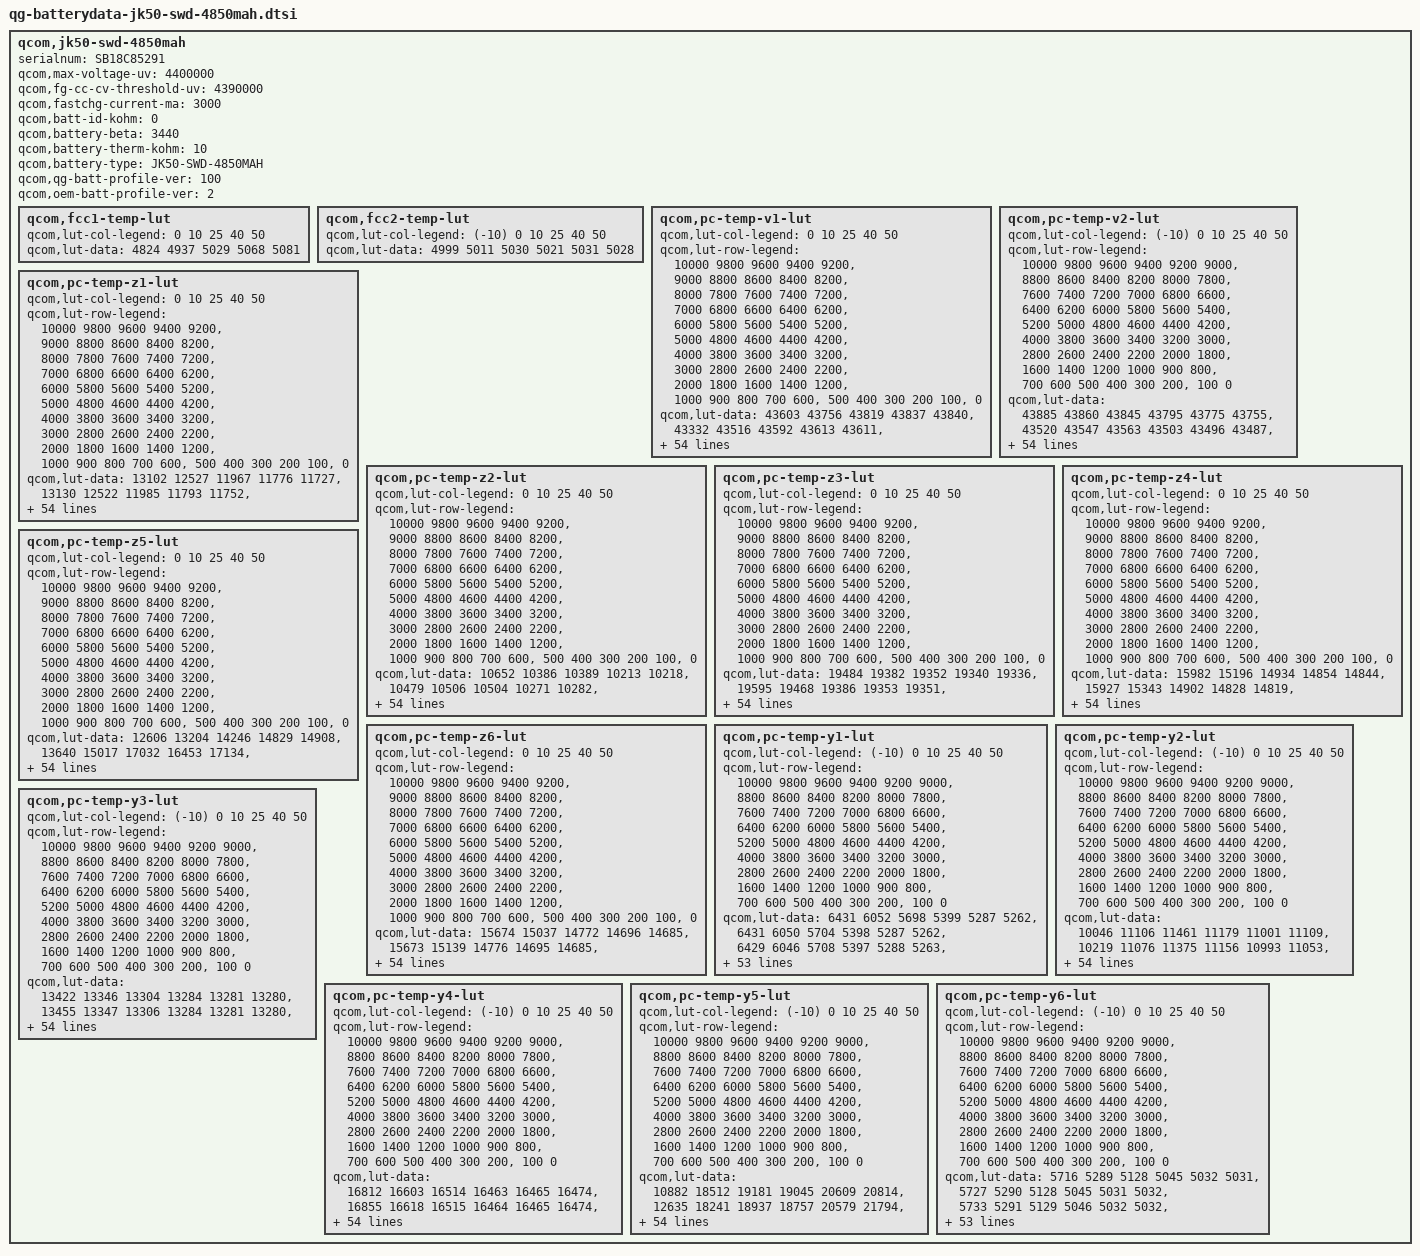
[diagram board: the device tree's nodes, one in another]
qcom,jk50-swd-4850mah {
    /* 4625982_SunWoda_P270AE_4850mAH_PMI632_averaged_MasterSlave_Jun9th2020 */
    serialnum = "SB18C85291";
    qcom,max-voltage-uv = <4400000>;
    qcom,fg-cc-cv-threshold-uv = <4390000>;
    qcom,fastchg-current-ma = <3000>;
    qcom,batt-id-kohm = <0>;
    qcom,battery-beta = <3440>;
    qcom,battery-therm-kohm = <10>;
    qcom,battery-type = "JK50-SWD-4850MAH";
    qcom,qg-batt-profile-ver = <100>;
    qcom,oem-batt-profile-ver = <2>;

	qcom,fcc1-temp-lut {
		qcom,lut-col-legend = <0 10 25 40 50>;
		qcom,lut-data = <4824 4937 5029 5068 5081>;
	};

	qcom,fcc2-temp-lut {
		qcom,lut-col-legend = <(-10) 0 10 25 40 50>;
		qcom,lut-data = <4999 5011 5030 5021 5031 5028>;
	};

	qcom,pc-temp-v1-lut {
		qcom,lut-col-legend = <0 10 25 40 50>;
		qcom,lut-row-legend = <10000 9800 9600 9400 9200>,
			<9000 8800 8600 8400 8200>,
			<8000 7800 7600 7400 7200>,
			<7000 6800 6600 6400 6200>,
			<6000 5800 5600 5400 5200>,
			<5000 4800 4600 4400 4200>,
			<4000 3800 3600 3400 3200>,
			<3000 2800 2600 2400 2200>,
			<2000 1800 1600 1400 1200>,
			<1000 900 800 700 600>,
			<500 400 300 200 100>,
			<0>;
		qcom,lut-data = <43603 43756 43819 43837 43840>,
			<43332 43516 43592 43613 43611>,
			<43073 43260 43358 43387 43393>,
			<42828 43019 43116 43153 43160>,
			<42594 42777 42871 42916 42925>,
			<42367 42538 42631 42678 42691>,
			<42146 42306 42393 42441 42457>,
			<41930 42082 42158 42205 42223>,
			<41716 41863 41927 41973 41990>,
			<41505 41643 41700 41743 41756>,
			<41311 41424 41474 41515 41527>,
			<41149 41227 41256 41291 41303>,
			<40979 41066 41060 41075 41084>,
			<40729 40893 40888 40872 40871>,
			<40397 40628 40693 40672 40663>,
			<40135 40304 40424 40464 40465>,
			<39962 40082 40161 40257 40275>,
			<39822 39942 39999 40076 40094>,
			<39697 39818 39879 39916 39921>,
			<39591 39690 39745 39757 39752>,
			<39477 39561 39596 39600 39593>,
			<39345 39383 39421 39433 39430>,
			<39205 39122 39160 39212 39222>,
			<39063 38889 38868 38944 38967>,
			<38915 38726 38717 38767 38775>,
			<38770 38596 38637 38668 38651>,
			<38620 38512 38564 38583 38550>,
			<38487 38453 38484 38483 38451>,
			<38406 38399 38407 38386 38362>,
			<38348 38345 38336 38301 38283>,
			<38304 38294 38270 38229 38213>,
			<38268 38247 38207 38163 38148>,
			<38238 38204 38150 38108 38090>,
			<38212 38165 38096 38055 38034>,
			<38190 38129 38050 38001 37975>,
			<38166 38094 38007 37947 37913>,
			<38141 38060 37964 37893 37852>,
			<38111 38026 37924 37844 37797>,
			<38064 37979 37872 37785 37732>,
			<37986 37899 37790 37697 37638>,
			<37889 37797 37684 37586 37522>,
			<37766 37682 37572 37471 37403>,
			<37624 37548 37446 37344 37275>,
			<37465 37392 37295 37197 37121>,
			<37327 37246 37151 37058 36981>,
			<37224 37153 37061 36974 36913>,
			<37195 37123 37032 36944 36888>,
			<37176 37099 37014 36924 36864>,
			<37149 37086 36996 36903 36842>,
			<37107 37049 36953 36852 36782>,
			<36918 36843 36738 36608 36514>,
			<36488 36418 36313 36171 36071>,
			<35914 35849 35743 35598 35495>,
			<35136 35066 34962 34814 34707>,
			<33915 33848 33751 33593 33479>,
			<30000 30000 30000 30000 30000>;
	};

	qcom,pc-temp-v2-lut {
		qcom,lut-col-legend = <(-10) 0 10 25 40 50>;
		qcom,lut-row-legend = <10000 9800 9600 9400 9200 9000>,
			<8800 8600 8400 8200 8000 7800>,
			<7600 7400 7200 7000 6800 6600>,
			<6400 6200 6000 5800 5600 5400>,
			<5200 5000 4800 4600 4400 4200>,
			<4000 3800 3600 3400 3200 3000>,
			<2800 2600 2400 2200 2000 1800>,
			<1600 1400 1200 1000 900 800>,
			<700 600 500 400 300 200>,
			<100 0>;
		qcom,lut-data = <43885 43860 43845 43795 43775 43755>,
			<43520 43547 43563 43503 43496 43487>,
			<43189 43251 43292 43227 43229 43228>,
			<42899 42976 43032 42968 42976 42980>,
			<42644 42719 42782 42724 42735 42742>,
			<42394 42470 42536 42485 42497 42505>,
			<42136 42224 42293 42246 42260 42267>,
			<41883 41985 42055 42011 42024 42029>,
			<41637 41754 41826 41780 41792 41796>,
			<41398 41529 41602 41552 41563 41564>,
			<41197 41318 41382 41329 41337 41337>,
			<41046 41125 41162 41110 41114 41114>,
			<40877 40930 40951 40898 40898 40897>,
			<40596 40724 40768 40707 40693 40690>,
			<40235 40503 40589 40523 40494 40488>,
			<39925 40226 40359 40313 40297 40293>,
			<39645 39863 40065 40075 40100 40102>,
			<39421 39579 39807 39868 39916 39920>,
			<39268 39425 39620 39725 39754 39754>,
			<39137 39299 39449 39589 39592 39588>,
			<38989 39141 39256 39393 39402 39404>,
			<38830 38965 39055 39147 39191 39205>,
			<38668 38803 38880 38932 38987 39005>,
			<38488 38658 38730 38749 38781 38791>,
			<38325 38524 38595 38592 38602 38603>,
			<38216 38403 38475 38468 38471 38470>,
			<38132 38292 38367 38363 38363 38361>,
			<38066 38186 38269 38268 38265 38260>,
			<38015 38079 38178 38181 38174 38167>,
			<37969 37991 38095 38102 38093 38083>,
			<37924 37931 38017 38027 38021 38011>,
			<37881 37882 37946 37958 37955 37943>,
			<37837 37842 37883 37897 37891 37880>,
			<37791 37808 37826 37843 37830 37821>,
			<37744 37778 37778 37788 37765 37754>,
			<37696 37751 37739 37733 37694 37671>,
			<37644 37722 37700 37675 37620 37581>,
			<37585 37683 37656 37612 37538 37487>,
			<37517 37634 37608 37545 37452 37390>,
			<37443 37573 37548 37470 37369 37302>,
			<37363 37495 37468 37387 37290 37225>,
			<37279 37383 37370 37292 37201 37137>,
			<37190 37219 37248 37179 37092 37029>,
			<37105 37092 37106 37042 36939 36873>,
			<37018 36986 36982 36921 36835 36774>,
			<36923 36895 36916 36874 36799 36740>,
			<36875 36849 36896 36862 36788 36730>,
			<36828 36804 36874 36847 36773 36713>,
			<36776 36742 36838 36820 36745 36684>,
			<36694 36648 36766 36747 36654 36578>,
			<36515 36470 36552 36504 36357 36256>,
			<36143 36096 36094 36014 35858 35745>,
			<35559 35497 35451 35380 35206 35084>,
			<34714 34662 34571 34523 34306 34164>,
			<33378 33410 33306 33242 32978 32845>,
			<29173 28085 28060 28142 28137 28100>;
	};

	qcom,pc-temp-z1-lut {
		qcom,lut-col-legend = <0 10 25 40 50>;
		qcom,lut-row-legend = <10000 9800 9600 9400 9200>,
			<9000 8800 8600 8400 8200>,
			<8000 7800 7600 7400 7200>,
			<7000 6800 6600 6400 6200>,
			<6000 5800 5600 5400 5200>,
			<5000 4800 4600 4400 4200>,
			<4000 3800 3600 3400 3200>,
			<3000 2800 2600 2400 2200>,
			<2000 1800 1600 1400 1200>,
			<1000 900 800 700 600>,
			<500 400 300 200 100>,
			<0>;
		qcom,lut-data = <13102 12527 11967 11776 11727>,
			<13130 12522 11985 11793 11752>,
			<13140 12523 11983 11793 11754>,
			<13130 12522 11980 11793 11756>,
			<13096 12514 11977 11794 11758>,
			<13076 12492 11974 11795 11759>,
			<13070 12479 11971 11795 11761>,
			<13066 12476 11969 11796 11763>,
			<13061 12474 11967 11798 11767>,
			<13056 12472 11966 11802 11771>,
			<13049 12467 11971 11805 11775>,
			<13036 12462 11980 11810 11779>,
			<13018 12457 11981 11811 11782>,
			<12991 12450 11977 11811 11784>,
			<12954 12438 11974 11811 11785>,
			<12937 12421 11968 11812 11787>,
			<12936 12417 11964 11814 11789>,
			<12937 12424 11966 11816 11791>,
			<12940 12433 11972 11818 11793>,
			<12950 12446 11978 11821 11795>,
			<12963 12461 11984 11823 11797>,
			<12984 12465 11988 11825 11799>,
			<13004 12463 11990 11827 11802>,
			<13008 12463 11992 11828 11804>,
			<13002 12467 11995 11831 11807>,
			<12999 12473 11999 11834 11810>,
			<13002 12476 12004 11838 11813>,
			<13006 12479 12008 11842 11816>,
			<13014 12482 12014 11845 11819>,
			<13030 12492 12019 11848 11822>,
			<13040 12504 12024 11852 11825>,
			<13041 12511 12029 11856 11828>,
			<13042 12515 12035 11859 11832>,
			<13043 12521 12040 11863 11836>,
			<13048 12529 12046 11867 11840>,
			<13053 12537 12053 11872 11843>,
			<13064 12542 12059 11876 11846>,
			<13079 12547 12063 11879 11849>,
			<13091 12554 12068 11883 11852>,
			<13103 12567 12074 11887 11855>,
			<13113 12579 12080 11891 11858>,
			<13124 12585 12087 11895 11861>,
			<13138 12590 12095 11899 11864>,
			<13158 12600 12100 11903 11867>,
			<13166 12619 12107 11906 11870>,
			<13177 12617 12116 11909 11871>,
			<13163 12614 12113 11908 11871>,
			<13142 12623 12113 11909 11871>,
			<13142 12616 12117 11911 11874>,
			<13147 12631 12125 11915 11878>,
			<13173 12634 12129 11920 11883>,
			<13170 12653 12138 11929 11889>,
			<13213 12677 12156 11940 11899>,
			<13255 12701 12183 11957 11913>,
			<13255 12701 12183 11957 11913>,
			<13255 12701 12183 11957 11913>;
	};

	qcom,pc-temp-z2-lut {
		qcom,lut-col-legend = <0 10 25 40 50>;
		qcom,lut-row-legend = <10000 9800 9600 9400 9200>,
			<9000 8800 8600 8400 8200>,
			<8000 7800 7600 7400 7200>,
			<7000 6800 6600 6400 6200>,
			<6000 5800 5600 5400 5200>,
			<5000 4800 4600 4400 4200>,
			<4000 3800 3600 3400 3200>,
			<3000 2800 2600 2400 2200>,
			<2000 1800 1600 1400 1200>,
			<1000 900 800 700 600>,
			<500 400 300 200 100>,
			<0>;
		qcom,lut-data = <10652 10386 10389 10213 10218>,
			<10479 10506 10504 10271 10282>,
			<10383 10499 10530 10291 10237>,
			<10382 10496 10521 10353 10297>,
			<10384 10481 10511 10392 10365>,
			<10388 10443 10493 10399 10383>,
			<10398 10420 10469 10389 10344>,
			<10406 10526 10446 10376 10310>,
			<10401 10658 10422 10359 10314>,
			<10379 10606 10408 10341 10323>,
			<10359 10419 10415 10339 10320>,
			<10344 10361 10425 10349 10306>,
			<10328 10612 10419 10346 10294>,
			<10305 10848 10388 10297 10284>,
			<10277 10748 10373 10256 10277>,
			<10262 10500 10430 10296 10263>,
			<10261 10426 10494 10376 10228>,
			<10264 10427 10477 10381 10225>,
			<10272 10431 10417 10310 10246>,
			<10287 10453 10403 10268 10272>,
			<10305 10503 10463 10291 10296>,
			<10325 10562 10531 10323 10318>,
			<10349 10644 10570 10333 10334>,
			<10376 10690 10600 10338 10349>,
			<10409 10667 10584 10345 10409>,
			<10437 10630 10479 10357 11039>,
			<10464 10616 10419 10378 11620>,
			<10484 10608 10457 10543 11401>,
			<10486 10604 10512 10807 10861>,
			<10484 10598 10537 10826 10571>,
			<10482 10591 10555 10662 10418>,
			<10481 10592 10566 10498 10312>,
			<10479 10598 10576 10361 10226>,
			<10480 10606 10583 10263 10172>,
			<10483 10619 10579 10249 10175>,
			<10488 10633 10570 10257 10206>,
			<10494 10644 10570 10278 10248>,
			<10503 10652 10587 10340 10322>,
			<10515 10664 10612 10406 10400>,
			<10533 10687 10662 10458 10468>,
			<10549 10704 10714 10501 10523>,
			<10558 10703 10723 10516 10526>,
			<10568 10700 10725 10522 10503>,
			<10581 10702 10723 10511 10489>,
			<10733 10749 10722 10500 10484>,
			<10872 10827 10657 10525 10488>,
			<10825 10835 10632 10522 10480>,
			<10828 10834 10648 10517 10482>,
			<10830 11080 10669 10535 10528>,
			<10802 11197 10743 10667 10614>,
			<10809 10976 10736 10575 10534>,
			<10662 10923 10640 10359 10255>,
			<10349 10795 10576 10259 10145>,
			<10155 10647 10503 10183 10078>,
			<10155 10647 10503 10183 10078>,
			<10155 10647 10503 10183 10078>;
	};

	qcom,pc-temp-z3-lut {
		qcom,lut-col-legend = <0 10 25 40 50>;
		qcom,lut-row-legend = <10000 9800 9600 9400 9200>,
			<9000 8800 8600 8400 8200>,
			<8000 7800 7600 7400 7200>,
			<7000 6800 6600 6400 6200>,
			<6000 5800 5600 5400 5200>,
			<5000 4800 4600 4400 4200>,
			<4000 3800 3600 3400 3200>,
			<3000 2800 2600 2400 2200>,
			<2000 1800 1600 1400 1200>,
			<1000 900 800 700 600>,
			<500 400 300 200 100>,
			<0>;
		qcom,lut-data = <19484 19382 19352 19340 19336>,
			<19595 19468 19386 19353 19351>,
			<19662 19507 19414 19374 19359>,
			<19669 19523 19428 19391 19382>,
			<19671 19527 19435 19398 19389>,
			<19670 19529 19436 19401 19392>,
			<19659 19530 19436 19405 19394>,
			<19645 19534 19436 19406 19395>,
			<19635 19536 19435 19406 19396>,
			<19628 19530 19433 19405 19397>,
			<19620 19514 19431 19403 19397>,
			<19607 19509 19428 19400 19393>,
			<19598 19518 19420 19395 19389>,
			<19606 19527 19401 19387 19386>,
			<19633 19521 19392 19382 19382>,
			<19645 19504 19402 19381 19378>,
			<19623 19487 19414 19381 19373>,
			<19593 19472 19409 19380 19369>,
			<19575 19459 19392 19373 19365>,
			<19561 19452 19385 19367 19362>,
			<19556 19447 19383 19364 19358>,
			<19558 19449 19383 19361 19355>,
			<19561 19468 19387 19358 19350>,
			<19566 19481 19395 19355 19344>,
			<19575 19479 19394 19350 19344>,
			<19582 19475 19380 19342 19387>,
			<19586 19471 19372 19337 19427>,
			<19589 19465 19373 19361 19427>,
			<19588 19462 19375 19403 19420>,
			<19583 19461 19378 19411 19413>,
			<19578 19459 19385 19406 19403>,
			<19573 19459 19391 19399 19392>,
			<19568 19458 19396 19390 19383>,
			<19563 19457 19398 19380 19373>,
			<19558 19457 19397 19372 19365>,
			<19553 19457 19393 19366 19357>,
			<19546 19455 19388 19359 19350>,
			<19540 19450 19380 19350 19342>,
			<19535 19446 19376 19344 19336>,
			<19531 19444 19376 19344 19333>,
			<19528 19441 19375 19343 19332>,
			<19523 19438 19374 19345 19334>,
			<19516 19434 19370 19349 19342>,
			<19509 19430 19368 19349 19349>,
			<19467 19420 19366 19348 19352>,
			<19438 19397 19354 19340 19341>,
			<19388 19394 19351 19336 19331>,
			<19308 19391 19345 19329 19323>,
			<19301 19333 19340 19324 19313>,
			<19296 19324 19337 19314 19309>,
			<19301 19379 19339 19330 19327>,
			<19311 19376 19349 19351 19345>,
			<19320 19353 19349 19355 19347>,
			<19317 19350 19348 19352 19349>,
			<19317 19350 19348 19352 19349>,
			<19317 19350 19348 19352 19349>;
	};

	qcom,pc-temp-z4-lut {
		qcom,lut-col-legend = <0 10 25 40 50>;
		qcom,lut-row-legend = <10000 9800 9600 9400 9200>,
			<9000 8800 8600 8400 8200>,
			<8000 7800 7600 7400 7200>,
			<7000 6800 6600 6400 6200>,
			<6000 5800 5600 5400 5200>,
			<5000 4800 4600 4400 4200>,
			<4000 3800 3600 3400 3200>,
			<3000 2800 2600 2400 2200>,
			<2000 1800 1600 1400 1200>,
			<1000 900 800 700 600>,
			<500 400 300 200 100>,
			<0>;
		qcom,lut-data = <15982 15196 14934 14854 14844>,
			<15927 15343 14902 14828 14819>,
			<15841 15263 14971 14855 14814>,
			<15713 15131 14928 14866 14857>,
			<15534 15044 14868 14836 14836>,
			<15391 14975 14832 14810 14815>,
			<15289 14915 14803 14788 14795>,
			<15207 14853 14778 14768 14776>,
			<15144 14807 14757 14750 14759>,
			<15094 14794 14740 14734 14743>,
			<15042 14788 14726 14723 14731>,
			<14981 14773 14715 14713 14722>,
			<14926 14712 14706 14706 14716>,
			<14895 14660 14699 14700 14712>,
			<14874 14680 14696 14696 14710>,
			<14855 14729 14706 14695 14707>,
			<14832 14742 14717 14695 14705>,
			<14810 14723 14709 14694 14701>,
			<14791 14703 14684 14685 14696>,
			<14774 14695 14676 14680 14693>,
			<14761 14689 14677 14681 14693>,
			<14751 14695 14680 14685 14696>,
			<14745 14748 14732 14717 14720>,
			<14746 14796 14822 14804 14799>,
			<14752 14819 14839 14834 14830>,
			<14760 14834 14829 14827 14769>,
			<14785 14832 14816 14815 14709>,
			<14811 14813 14801 14775 14702>,
			<14814 14793 14783 14718 14699>,
			<14810 14778 14763 14700 14696>,
			<14805 14765 14743 14695 14693>,
			<14797 14752 14726 14690 14690>,
			<14787 14740 14710 14686 14683>,
			<14777 14730 14698 14683 14677>,
			<14767 14722 14693 14680 14675>,
			<14757 14715 14689 14678 14673>,
			<14746 14709 14686 14677 14673>,
			<14736 14703 14684 14676 14672>,
			<14727 14701 14683 14676 14672>,
			<14719 14700 14688 14684 14683>,
			<14713 14700 14694 14698 14702>,
			<14710 14697 14694 14698 14703>,
			<14707 14690 14689 14692 14693>,
			<14700 14685 14688 14693 14695>,
			<14692 14672 14682 14692 14696>,
			<14683 14656 14659 14664 14662>,
			<14735 14651 14654 14660 14661>,
			<14818 14647 14647 14651 14653>,
			<14820 14702 14635 14632 14637>,
			<14814 14704 14631 14629 14625>,
			<14806 14650 14653 14655 14660>,
			<14815 14666 14661 14660 14674>,
			<14818 14700 14666 14663 14680>,
			<14838 14712 14672 14672 14685>,
			<14838 14712 14672 14672 14685>,
			<14838 14712 14672 14672 14685>;
	};

	qcom,pc-temp-z5-lut {
		qcom,lut-col-legend = <0 10 25 40 50>;
		qcom,lut-row-legend = <10000 9800 9600 9400 9200>,
			<9000 8800 8600 8400 8200>,
			<8000 7800 7600 7400 7200>,
			<7000 6800 6600 6400 6200>,
			<6000 5800 5600 5400 5200>,
			<5000 4800 4600 4400 4200>,
			<4000 3800 3600 3400 3200>,
			<3000 2800 2600 2400 2200>,
			<2000 1800 1600 1400 1200>,
			<1000 900 800 700 600>,
			<500 400 300 200 100>,
			<0>;
		qcom,lut-data = <12606 13204 14246 14829 14908>,
			<13640 15017 17032 16453 17134>,
			<14419 16156 17679 18298 18331>,
			<14878 16741 18570 19288 20053>,
			<15193 17395 19788 20317 21209>,
			<15474 17989 20583 21323 22130>,
			<15754 18700 21260 22378 22790>,
			<16026 19850 21997 23450 23557>,
			<16290 20854 22800 24532 25069>,
			<16544 21076 23699 25635 27027>,
			<16827 21094 25059 26897 28508>,
			<17105 21756 26377 28343 29750>,
			<17493 28446 25904 28787 30801>,
			<19092 34627 22845 28167 31813>,
			<22690 33836 21365 27606 32536>,
			<24235 31056 26114 29427 32707>,
			<23121 28735 31560 33068 32759>,
			<21844 26577 30725 33745 33134>,
			<21798 25376 27305 32970 34902>,
			<22249 26235 26313 32498 36086>,
			<22992 28897 28419 32947 35875>,
			<25194 35208 31210 33509 35288>,
			<28809 54343 33955 32163 32691>,
			<33716 65535 36484 27429 25564>,
			<41116 59708 35346 23193 23019>,
			<46514 47596 26933 19140 30629>,
			<50348 40666 21492 16813 38193>,
			<53213 35840 20613 20996 39141>,
			<52568 33350 20174 28997 39553>,
			<48491 32406 20531 32006 39328>,
			<44646 31882 22130 33452 37442>,
			<42065 32035 24282 33939 35552>,
			<39909 32952 27942 32628 34168>,
			<38336 34227 31598 31123 33110>,
			<37078 36726 34111 31298 32770>,
			<36185 39132 36053 32030 32630>,
			<35477 39859 36130 32074 32236>,
			<34987 40245 34356 30194 30576>,
			<35431 40535 33234 28478 28559>,
			<37739 40888 33630 28076 26644>,
			<39132 41121 34170 27811 24984>,
			<38303 40046 33029 27287 24990>,
			<36980 37699 29713 26531 26493>,
			<35869 36162 29536 26732 29841>,
			<29912 36129 30410 27888 32643>,
			<25852 31058 28866 26490 29251>,
			<19231 29316 27322 23726 21801>,
			<12577 28392 24788 21991 20419>,
			<12394 15471 24975 24371 20361>,
			<12363 14575 25246 22014 22210>,
			<12651 26666 22963 24025 23861>,
			<12729 21636 21465 23727 21448>,
			<12748 16396 19553 21510 18724>,
			<12337 15438 17869 17602 16232>,
			<12337 15438 17869 17602 16232>,
			<12337 15438 17869 17602 16232>;
	};

	qcom,pc-temp-z6-lut {
		qcom,lut-col-legend = <0 10 25 40 50>;
		qcom,lut-row-legend = <10000 9800 9600 9400 9200>,
			<9000 8800 8600 8400 8200>,
			<8000 7800 7600 7400 7200>,
			<7000 6800 6600 6400 6200>,
			<6000 5800 5600 5400 5200>,
			<5000 4800 4600 4400 4200>,
			<4000 3800 3600 3400 3200>,
			<3000 2800 2600 2400 2200>,
			<2000 1800 1600 1400 1200>,
			<1000 900 800 700 600>,
			<500 400 300 200 100>,
			<0>;
		qcom,lut-data = <15674 15037 14772 14696 14685>,
			<15673 15139 14776 14695 14685>,
			<15670 15113 14821 14719 14687>,
			<15637 15069 14807 14730 14716>,
			<15541 15033 14787 14723 14713>,
			<15460 14999 14773 14716 14709>,
			<15403 14970 14760 14708 14702>,
			<15355 14945 14749 14701 14695>,
			<15318 14924 14739 14694 14689>,
			<15288 14911 14731 14688 14684>,
			<15257 14901 14725 14682 14679>,
			<15216 14888 14720 14677 14673>,
			<15180 14864 14711 14671 14669>,
			<15164 14847 14697 14664 14665>,
			<15154 14848 14691 14659 14662>,
			<15141 14852 14699 14658 14659>,
			<15117 14851 14709 14658 14655>,
			<15091 14836 14703 14656 14651>,
			<15078 14822 14684 14649 14647>,
			<15068 14817 14678 14644 14644>,
			<15065 14814 14678 14643 14642>,
			<15065 14819 14679 14643 14641>,
			<15067 14853 14704 14655 14649>,
			<15071 14881 14747 14690 14681>,
			<15080 14890 14754 14703 14694>,
			<15091 14895 14745 14696 14692>,
			<15106 14894 14735 14689 14689>,
			<15120 14884 14729 14686 14686>,
			<15122 14875 14724 14685 14682>,
			<15120 14870 14719 14682 14678>,
			<15118 14865 14715 14677 14672>,
			<15114 14861 14711 14672 14666>,
			<15108 14857 14708 14666 14658>,
			<15104 14854 14705 14660 14651>,
			<15100 14853 14702 14655 14646>,
			<15096 14852 14699 14651 14641>,
			<15091 14849 14696 14647 14637>,
			<15087 14847 14692 14642 14632>,
			<15087 14846 14690 14639 14629>,
			<15087 14848 14693 14642 14632>,
			<15088 14849 14696 14648 14639>,
			<15090 14849 14696 14649 14641>,
			<15091 14847 14694 14649 14642>,
			<15091 14846 14693 14650 14646>,
			<15080 14841 14691 14650 14648>,
			<15068 14827 14676 14633 14628>,
			<15064 14823 14672 14630 14623>,
			<15059 14820 14666 14622 14615>,
			<15056 14815 14658 14612 14603>,
			<15057 14815 14657 14606 14596>,
			<15064 14823 14667 14625 14621>,
			<15080 14835 14679 14642 14639>,
			<15098 14845 14686 14648 14646>,
			<15125 14862 14694 14654 14653>,
			<15125 14862 14694 14654 14653>,
			<15125 14862 14694 14654 14653>;
	};

	qcom,pc-temp-y1-lut {
		qcom,lut-col-legend = <(-10) 0 10 25 40 50>;
		qcom,lut-row-legend = <10000 9800 9600 9400 9200 9000>,
			<8800 8600 8400 8200 8000 7800>,
			<7600 7400 7200 7000 6800 6600>,
			<6400 6200 6000 5800 5600 5400>,
			<5200 5000 4800 4600 4400 4200>,
			<4000 3800 3600 3400 3200 3000>,
			<2800 2600 2400 2200 2000 1800>,
			<1600 1400 1200 1000 900 800>,
			<700 600 500 400 300 200>,
			<100 0>;
		qcom,lut-data = <6431 6052 5698 5399 5287 5262>,
			<6431 6050 5704 5398 5287 5262>,
			<6429 6046 5708 5397 5288 5263>,
			<6426 6040 5711 5396 5288 5264>,
			<6424 6033 5712 5395 5288 5265>,
			<6423 6025 5711 5394 5288 5265>,
			<6421 6012 5708 5393 5288 5265>,
			<6419 6002 5705 5393 5287 5265>,
			<6425 6003 5703 5392 5288 5265>,
			<6441 6010 5702 5391 5288 5266>,
			<6447 6012 5700 5391 5288 5267>,
			<6435 6007 5694 5390 5288 5267>,
			<6425 6002 5690 5390 5288 5267>,
			<6428 6001 5688 5389 5289 5268>,
			<6434 6000 5687 5388 5290 5269>,
			<6432 6004 5688 5390 5291 5271>,
			<6425 6018 5694 5396 5293 5272>,
			<6420 6030 5700 5400 5294 5273>,
			<6429 6037 5704 5400 5295 5274>,
			<6444 6042 5707 5400 5296 5275>,
			<6441 6039 5707 5401 5297 5276>,
			<6423 6025 5706 5404 5298 5277>,
			<6414 6019 5707 5407 5300 5278>,
			<6424 6024 5709 5410 5302 5280>,
			<6438 6028 5711 5412 5305 5282>,
			<6451 6029 5713 5416 5307 5284>,
			<6467 6028 5715 5420 5309 5286>,
			<6471 6029 5718 5424 5311 5289>,
			<6466 6034 5720 5427 5314 5292>,
			<6459 6037 5723 5431 5316 5294>,
			<6440 6037 5727 5435 5319 5296>,
			<6414 6036 5732 5439 5321 5298>,
			<6410 6037 5734 5443 5324 5300>,
			<6421 6043 5736 5447 5328 5302>,
			<6427 6046 5736 5450 5331 5304>,
			<6419 6039 5736 5453 5332 5307>,
			<6406 6032 5735 5455 5334 5308>,
			<6405 6034 5739 5456 5335 5309>,
			<6405 6041 5745 5457 5335 5310>,
			<6406 6046 5747 5458 5336 5311>,
			<6412 6061 5747 5460 5338 5312>,
			<6422 6065 5749 5462 5339 5313>,
			<6437 6055 5755 5466 5341 5315>,
			<6434 6073 5769 5470 5343 5318>,
			<6455 6064 5774 5477 5348 5321>,
			<6467 6072 5778 5484 5350 5322>,
			<6480 6070 5778 5484 5350 5322>,
			<6497 6091 5784 5484 5350 5322>,
			<6479 6087 5789 5484 5350 5323>,
			<6520 6100 5787 5484 5352 5324>,
			<6491 6094 5791 5487 5354 5327>,
			<6540 6119 5803 5499 5360 5332>,
			<6554 6139 5821 5513 5369 5339>,
			<6584 6180 5844 5535 5381 5348>,
			<6584 6180 5844 5535 5381 5348>,
			<6584 6180 5844 5535 5381 5348>;
	};

	qcom,pc-temp-y2-lut {
		qcom,lut-col-legend = <(-10) 0 10 25 40 50>;
		qcom,lut-row-legend = <10000 9800 9600 9400 9200 9000>,
			<8800 8600 8400 8200 8000 7800>,
			<7600 7400 7200 7000 6800 6600>,
			<6400 6200 6000 5800 5600 5400>,
			<5200 5000 4800 4600 4400 4200>,
			<4000 3800 3600 3400 3200 3000>,
			<2800 2600 2400 2200 2000 1800>,
			<1600 1400 1200 1000 900 800>,
			<700 600 500 400 300 200>,
			<100 0>;
		qcom,lut-data = <10046 11106 11461 11179 11001 11109>,
			<10219 11076 11375 11156 10993 11053>,
			<10348 11042 11285 11123 10977 10999>,
			<10437 11009 11201 11087 10955 10949>,
			<10487 10982 11131 11051 10930 10906>,
			<10499 10963 11084 11018 10903 10873>,
			<10445 10948 11050 10983 10867 10848>,
			<10386 10939 11030 10950 10835 10828>,
			<10432 10944 11028 10927 10820 10813>,
			<10590 10958 11028 10908 10811 10800>,
			<10716 10962 11029 10902 10803 10785>,
			<10820 10952 11041 10912 10795 10763>,
			<10879 10943 11061 10925 10786 10748>,
			<10864 11065 11093 10937 10770 10743>,
			<10832 11286 11140 10954 10753 10739>,
			<10838 11317 11204 10988 10753 10740>,
			<10922 11241 11298 11063 10771 10747>,
			<11013 11195 11346 11153 10803 10760>,
			<11091 11229 11352 11284 10921 10797>,
			<11151 11279 11355 11393 11085 10864>,
			<11155 11297 11362 11389 11226 11017>,
			<11139 11307 11372 11346 11363 11281>,
			<11090 11317 11384 11309 11388 11353>,
			<10496 11331 11400 11277 11236 11197>,
			<9852 11344 11418 11257 11109 11066>,
			<9756 11356 11438 11279 11126 11081>,
			<9722 11368 11458 11333 11172 11123>,
			<9706 11378 11476 11379 11227 11165>,
			<9697 11388 11494 11428 11305 11212>,
			<9691 11393 11507 11464 11344 11262>,
			<9686 11390 11515 11487 11338 11314>,
			<9683 11383 11521 11504 11330 11362>,
			<9679 11280 11523 11512 11333 11409>,
			<9676 10884 11522 11522 11343 11484>,
			<9673 10687 11519 11523 11351 11502>,
			<9670 10936 11504 11506 11353 11405>,
			<9668 11211 11482 11482 11347 11309>,
			<9665 11197 11450 11453 11309 11294>,
			<9664 11130 11406 11417 11248 11288>,
			<9662 11053 11367 11402 11236 11270>,
			<9661 10969 11332 11396 11245 11216>,
			<9660 10667 11287 11384 11254 11191>,
			<9660 9755 11230 11359 11248 11172>,
			<9659 9701 11167 11352 11239 11117>,
			<9658 9700 11144 11278 11106 10993>,
			<9658 9680 11043 11184 10940 10845>,
			<9657 9673 11003 11182 10954 10822>,
			<9657 9668 10975 11215 11010 10840>,
			<9656 9665 10950 11246 11042 10904>,
			<9656 9662 10922 11274 10987 10902>,
			<9656 9661 10872 11248 10920 10855>,
			<9655 9659 10729 11124 10847 10717>,
			<9654 9656 10525 10998 10704 10591>,
			<9652 9655 10153 10889 10584 10418>,
			<9652 9655 10153 10889 10584 10418>,
			<9652 9655 10153 10889 10584 10418>;
	};

	qcom,pc-temp-y3-lut {
		qcom,lut-col-legend = <(-10) 0 10 25 40 50>;
		qcom,lut-row-legend = <10000 9800 9600 9400 9200 9000>,
			<8800 8600 8400 8200 8000 7800>,
			<7600 7400 7200 7000 6800 6600>,
			<6400 6200 6000 5800 5600 5400>,
			<5200 5000 4800 4600 4400 4200>,
			<4000 3800 3600 3400 3200 3000>,
			<2800 2600 2400 2200 2000 1800>,
			<1600 1400 1200 1000 900 800>,
			<700 600 500 400 300 200>,
			<100 0>;
		qcom,lut-data = <13422 13346 13304 13284 13281 13280>,
			<13455 13347 13306 13284 13281 13280>,
			<13475 13348 13308 13285 13281 13281>,
			<13486 13351 13309 13286 13282 13282>,
			<13491 13353 13311 13287 13282 13282>,
			<13491 13356 13312 13287 13283 13283>,
			<13480 13359 13313 13287 13284 13283>,
			<13468 13362 13315 13288 13285 13284>,
			<13485 13362 13317 13288 13286 13284>,
			<13532 13362 13320 13289 13286 13284>,
			<13540 13363 13322 13290 13287 13285>,
			<13454 13370 13323 13293 13287 13285>,
			<13379 13377 13323 13296 13287 13286>,
			<13389 13373 13326 13299 13289 13287>,
			<13409 13365 13328 13303 13291 13289>,
			<13412 13357 13328 13303 13291 13290>,
			<13400 13350 13324 13298 13291 13290>,
			<13389 13345 13321 13296 13291 13290>,
			<13386 13343 13318 13297 13293 13291>,
			<13383 13341 13316 13297 13294 13292>,
			<13378 13339 13313 13296 13293 13292>,
			<13370 13336 13309 13293 13290 13289>,
			<13364 13333 13306 13290 13287 13286>,
			<13358 13330 13304 13286 13282 13281>,
			<13354 13328 13303 13283 13279 13278>,
			<13352 13326 13302 13283 13279 13278>,
			<13348 13324 13301 13283 13279 13278>,
			<13347 13321 13301 13283 13278 13278>,
			<13346 13318 13301 13284 13277 13277>,
			<13347 13316 13301 13284 13276 13276>,
			<13355 13316 13301 13284 13277 13276>,
			<13369 13315 13300 13283 13277 13276>,
			<13385 13314 13300 13284 13277 13276>,
			<13405 13312 13300 13284 13278 13278>,
			<13429 13311 13300 13285 13278 13279>,
			<13461 13318 13300 13285 13279 13278>,
			<13499 13327 13301 13285 13280 13278>,
			<13543 13330 13301 13285 13280 13278>,
			<13594 13333 13303 13285 13279 13278>,
			<13649 13337 13305 13285 13280 13279>,
			<13706 13341 13307 13285 13281 13281>,
			<13768 13348 13307 13285 13282 13281>,
			<13836 13361 13308 13286 13282 13280>,
			<13916 13374 13306 13285 13278 13277>,
			<13924 13376 13305 13283 13278 13277>,
			<14070 13419 13309 13287 13285 13284>,
			<14153 13455 13313 13291 13288 13287>,
			<14245 13516 13317 13295 13291 13289>,
			<14345 13591 13323 13298 13293 13290>,
			<14448 13687 13331 13299 13291 13290>,
			<14566 13778 13335 13297 13288 13287>,
			<14736 13875 13337 13296 13289 13287>,
			<15139 14091 13350 13301 13294 13292>,
			<16028 14430 13390 13310 13303 13302>,
			<16028 14430 13390 13310 13303 13302>,
			<16028 14430 13390 13310 13303 13302>;
	};

	qcom,pc-temp-y4-lut {
		qcom,lut-col-legend = <(-10) 0 10 25 40 50>;
		qcom,lut-row-legend = <10000 9800 9600 9400 9200 9000>,
			<8800 8600 8400 8200 8000 7800>,
			<7600 7400 7200 7000 6800 6600>,
			<6400 6200 6000 5800 5600 5400>,
			<5200 5000 4800 4600 4400 4200>,
			<4000 3800 3600 3400 3200 3000>,
			<2800 2600 2400 2200 2000 1800>,
			<1600 1400 1200 1000 900 800>,
			<700 600 500 400 300 200>,
			<100 0>;
		qcom,lut-data = <16812 16603 16514 16463 16465 16474>,
			<16855 16618 16515 16464 16465 16474>,
			<16896 16634 16517 16465 16464 16474>,
			<16935 16649 16519 16465 16463 16473>,
			<16968 16661 16522 16467 16462 16472>,
			<16995 16669 16525 16468 16462 16471>,
			<17021 16672 16528 16471 16462 16470>,
			<17037 16676 16531 16474 16462 16468>,
			<17000 16687 16537 16478 16462 16467>,
			<16896 16708 16545 16481 16464 16467>,
			<16882 16725 16555 16485 16466 16467>,
			<17146 16735 16566 16487 16469 16468>,
			<17372 16748 16581 16491 16473 16470>,
			<17270 16800 16619 16499 16478 16472>,
			<17039 16872 16663 16513 16484 16476>,
			<16900 16860 16669 16527 16490 16479>,
			<16806 16718 16663 16542 16497 16484>,
			<16766 16633 16654 16561 16507 16491>,
			<16773 16645 16635 16594 16530 16507>,
			<16782 16661 16608 16623 16550 16524>,
			<16776 16655 16576 16608 16550 16532>,
			<16742 16623 16538 16552 16544 16538>,
			<16708 16599 16518 16510 16532 16536>,
			<16675 16585 16507 16481 16492 16498>,
			<16651 16573 16501 16465 16462 16464>,
			<16647 16564 16500 16465 16461 16461>,
			<16646 16556 16499 16466 16461 16460>,
			<16648 16544 16500 16467 16462 16461>,
			<16656 16523 16501 16471 16468 16466>,
			<16664 16511 16502 16476 16476 16473>,
			<16670 16512 16501 16481 16485 16481>,
			<16675 16514 16499 16486 16494 16491>,
			<16681 16524 16496 16491 16501 16501>,
			<16686 16555 16493 16497 16506 16513>,
			<16691 16574 16493 16498 16507 16517>,
			<16696 16582 16499 16496 16504 16513>,
			<16700 16591 16507 16492 16498 16506>,
			<16701 16605 16517 16489 16490 16496>,
			<16702 16629 16528 16486 16481 16485>,
			<16702 16640 16536 16486 16481 16484>,
			<16699 16644 16542 16487 16487 16494>,
			<16697 16644 16543 16488 16494 16503>,
			<16699 16642 16543 16489 16497 16506>,
			<16699 16639 16528 16471 16460 16459>,
			<16683 16623 16505 16455 16445 16443>,
			<16698 16645 16526 16473 16470 16481>,
			<16715 16665 16543 16490 16498 16516>,
			<16739 16693 16568 16514 16532 16554>,
			<16767 16738 16603 16548 16569 16587>,
			<16801 16786 16652 16568 16571 16574>,
			<16808 16832 16654 16538 16509 16503>,
			<16782 16843 16627 16502 16483 16487>,
			<16818 16842 16641 16515 16484 16484>,
			<17052 16879 16698 16552 16499 16492>,
			<17052 16879 16698 16552 16499 16492>,
			<17052 16879 16698 16552 16499 16492>;
	};

	qcom,pc-temp-y5-lut {
		qcom,lut-col-legend = <(-10) 0 10 25 40 50>;
		qcom,lut-row-legend = <10000 9800 9600 9400 9200 9000>,
			<8800 8600 8400 8200 8000 7800>,
			<7600 7400 7200 7000 6800 6600>,
			<6400 6200 6000 5800 5600 5400>,
			<5200 5000 4800 4600 4400 4200>,
			<4000 3800 3600 3400 3200 3000>,
			<2800 2600 2400 2200 2000 1800>,
			<1600 1400 1200 1000 900 800>,
			<700 600 500 400 300 200>,
			<100 0>;
		qcom,lut-data = <10882 18512 19181 19045 20609 20814>,
			<12635 18241 18937 18757 20579 21794>,
			<14240 17938 18662 18439 20415 22469>,
			<15545 17659 18360 18114 20199 22887>,
			<16396 17462 18032 17801 20012 23094>,
			<16635 17402 17677 17511 19931 23121>,
			<16149 17381 17214 16891 19895 22514>,
			<15608 17312 16843 16198 19833 21755>,
			<16902 17109 16731 15785 19561 21241>,
			<20483 16754 16660 15454 18917 20394>,
			<21379 16529 16554 15416 18233 19598>,
			<17526 16399 16256 15855 17318 18742>,
			<14257 16399 16053 16269 16779 18255>,
			<17212 17481 16105 16399 16882 18409>,
			<23001 19560 16265 16482 17053 18692>,
			<23826 20749 17266 16275 16866 18538>,
			<20766 21556 20988 15206 15891 17632>,
			<18811 21952 23094 14620 15387 16854>,
			<19765 22025 23341 15432 15467 16343>,
			<21273 22082 23465 17036 15662 16015>,
			<21956 22324 23464 19496 17378 17264>,
			<22397 22810 23410 23088 21574 20814>,
			<22433 23069 23299 24141 22903 21983>,
			<19252 23058 22766 21967 21782 21149>,
			<15427 23046 22309 19867 20528 20297>,
			<14228 23248 22329 19528 19900 20130>,
			<13545 23564 22507 19449 19339 20105>,
			<13276 23504 22754 19706 18568 19510>,
			<13225 22272 23217 20636 17363 17591>,
			<13267 21034 23789 21206 16780 16469>,
			<13360 20394 24708 21090 16904 16383>,
			<13495 19729 25516 20930 17190 16342>,
			<13654 18878 25587 21306 17798 16835>,
			<13870 17819 25536 22890 19133 18677>,
			<14107 17466 25390 24144 20689 20290>,
			<14479 19239 24429 24977 22952 21761>,
			<14823 21269 23410 25471 24499 22671>,
			<14862 21610 23055 24999 23858 22451>,
			<14842 21899 22808 23636 22417 21926>,
			<14803 22162 22512 22464 21890 21788>,
			<14633 22520 22157 21370 21872 22066>,
			<14362 21654 21575 21086 21970 21956>,
			<13965 15710 20765 21203 21947 21670>,
			<13943 14678 19961 22311 21238 21957>,
			<13910 14438 20665 20669 19236 18707>,
			<13948 14496 19714 18512 17747 16676>,
			<13822 14369 19290 18754 17071 15661>,
			<13895 14571 19015 18585 16477 14966>,
			<14253 14505 18642 18365 16065 14821>,
			<14566 15334 19306 17928 15481 14833>,
			<14673 16261 19834 18808 16122 15510>,
			<14148 16011 19227 19946 17444 15282>,
			<13149 14645 18330 20188 17834 16092>,
			<11690 13450 16842 22547 24111 23251>,
			<11690 13450 16842 22547 24111 23251>,
			<11690 13450 16842 22547 24111 23251>;
	};

	qcom,pc-temp-y6-lut {
		qcom,lut-col-legend = <(-10) 0 10 25 40 50>;
		qcom,lut-row-legend = <10000 9800 9600 9400 9200 9000>,
			<8800 8600 8400 8200 8000 7800>,
			<7600 7400 7200 7000 6800 6600>,
			<6400 6200 6000 5800 5600 5400>,
			<5200 5000 4800 4600 4400 4200>,
			<4000 3800 3600 3400 3200 3000>,
			<2800 2600 2400 2200 2000 1800>,
			<1600 1400 1200 1000 900 800>,
			<700 600 500 400 300 200>,
			<100 0>;
		qcom,lut-data = <5716 5289 5128 5045 5032 5031>,
			<5727 5290 5128 5045 5031 5032>,
			<5733 5291 5129 5046 5032 5032>,
			<5737 5292 5130 5047 5032 5033>,
			<5738 5293 5130 5048 5033 5034>,
			<5738 5294 5131 5049 5033 5034>,
			<5730 5295 5132 5050 5034 5034>,
			<5721 5295 5133 5051 5035 5034>,
			<5715 5297 5135 5052 5036 5034>,
			<5708 5300 5138 5054 5036 5034>,
			<5708 5304 5142 5056 5038 5035>,
			<5724 5309 5145 5058 5039 5036>,
			<5737 5316 5149 5061 5040 5037>,
			<5718 5328 5161 5066 5042 5038>,
			<5672 5342 5174 5073 5046 5040>,
			<5639 5336 5176 5077 5048 5042>,
			<5612 5294 5173 5079 5050 5044>,
			<5600 5268 5168 5082 5053 5046>,
			<5603 5271 5161 5091 5060 5052>,
			<5608 5275 5152 5100 5067 5058>,
			<5607 5272 5140 5095 5067 5058>,
			<5600 5261 5127 5077 5062 5057>,
			<5592 5254 5119 5062 5056 5055>,
			<5579 5250 5116 5052 5041 5040>,
			<5569 5248 5114 5045 5030 5028>,
			<5571 5247 5114 5046 5030 5028>,
			<5579 5247 5114 5046 5030 5028>,
			<5589 5246 5115 5047 5030 5028>,
			<5606 5243 5116 5049 5032 5029>,
			<5625 5241 5117 5051 5034 5030>,
			<5646 5243 5118 5053 5036 5033>,
			<5670 5249 5119 5054 5039 5036>,
			<5696 5257 5119 5056 5042 5039>,
			<5725 5268 5120 5059 5044 5044>,
			<5758 5282 5120 5060 5045 5045>,
			<5797 5300 5124 5060 5044 5044>,
			<5839 5320 5128 5059 5043 5042>,
			<5884 5343 5133 5059 5041 5040>,
			<5933 5370 5139 5058 5039 5037>,
			<5983 5398 5145 5058 5039 5037>,
			<6034 5429 5151 5059 5042 5042>,
			<6087 5458 5157 5060 5044 5044>,
			<6143 5483 5161 5061 5045 5044>,
			<6212 5521 5160 5056 5033 5029>,
			<6227 5519 5154 5051 5029 5026>,
			<6351 5614 5173 5060 5042 5042>,
			<6422 5674 5185 5068 5052 5054>,
			<6502 5753 5201 5078 5064 5067>,
			<6588 5845 5221 5090 5076 5077>,
			<6680 5951 5250 5096 5076 5073>,
			<6785 6049 5260 5086 5055 5052>,
			<6914 6146 5268 5077 5050 5047>,
			<7268 6339 5324 5088 5055 5052>,
			<8064 6634 5441 5109 5067 5063>,
			<8064 6634 5441 5109 5067 5063>,
			<8064 6634 5441 5109 5067 5063>;
	};

};
